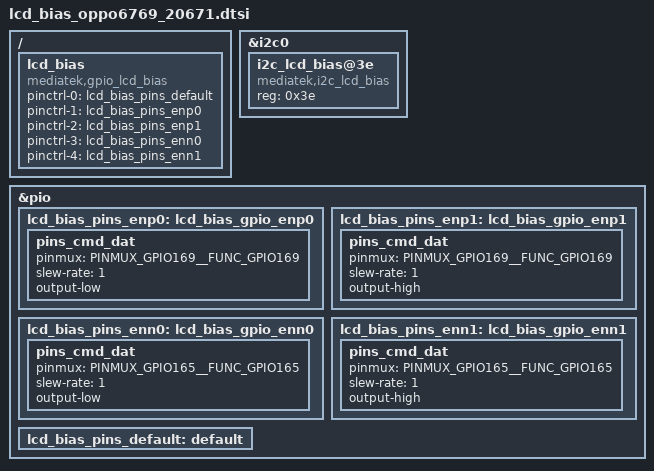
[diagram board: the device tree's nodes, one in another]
/********************************************
 ** Copyright (C) 2018 OPPO Mobile Comm Corp. Ltd.
 ** ODM_HQ_EDIT
 ** File: lcd_bias_oppo6769_20671.dtsi
 ** Description: Source file for LCD bias
 **          To Control LCD bias voltage
 ** Version :1.0
 ** Date : 2020/02/29
 ** Author: Liyan@ODM_HQ.Multimedia.LCD
 ** ---------------- Revision History: --------------------------
 ** <version>    <date>          < author >              <desc>
 **  1.0           2020/02/29   Liyan@ODM_HQ   Source file for LCD bias
 ********************************************/

/ {
	lcd_bias:lcd_bias {
		compatible = "mediatek,gpio_lcd_bias";
	};
};

&i2c0 {
	i2c_lcd_bias@3e {
		compatible = "mediatek,i2c_lcd_bias";
		reg = <0x3e>;
	};
};

&lcd_bias {
	pinctrl-names = "default", "lcd_bias_gpio_enp0", "lcd_bias_gpio_enp1", "lcd_bias_gpio_enn0", "lcd_bias_gpio_enn1";
	pinctrl-0 = <&lcd_bias_pins_default>;
	pinctrl-1 = <&lcd_bias_pins_enp0>;
	pinctrl-2 = <&lcd_bias_pins_enp1>;
	pinctrl-3 = <&lcd_bias_pins_enn0>;
	pinctrl-4 = <&lcd_bias_pins_enn1>;
	status = "okay";
};

&pio {
	lcd_bias_pins_enp0: lcd_bias_gpio_enp0 {
		pins_cmd_dat {
			pinmux = <PINMUX_GPIO169__FUNC_GPIO169>;
			slew-rate = <1>;
			output-low;
		};
	};

	lcd_bias_pins_enp1: lcd_bias_gpio_enp1 {
		pins_cmd_dat {
			pinmux = <PINMUX_GPIO169__FUNC_GPIO169>;
			slew-rate = <1>;
			output-high;
		};
	};

	lcd_bias_pins_enn0: lcd_bias_gpio_enn0 {
		pins_cmd_dat {
			pinmux = <PINMUX_GPIO165__FUNC_GPIO165>;
			slew-rate = <1>;
			output-low;
		};
	};

	lcd_bias_pins_enn1: lcd_bias_gpio_enn1 {
		pins_cmd_dat {
			pinmux = <PINMUX_GPIO165__FUNC_GPIO165>;
			slew-rate = <1>;
			output-high;
		};
	};

	lcd_bias_pins_default: default {
	};
};
